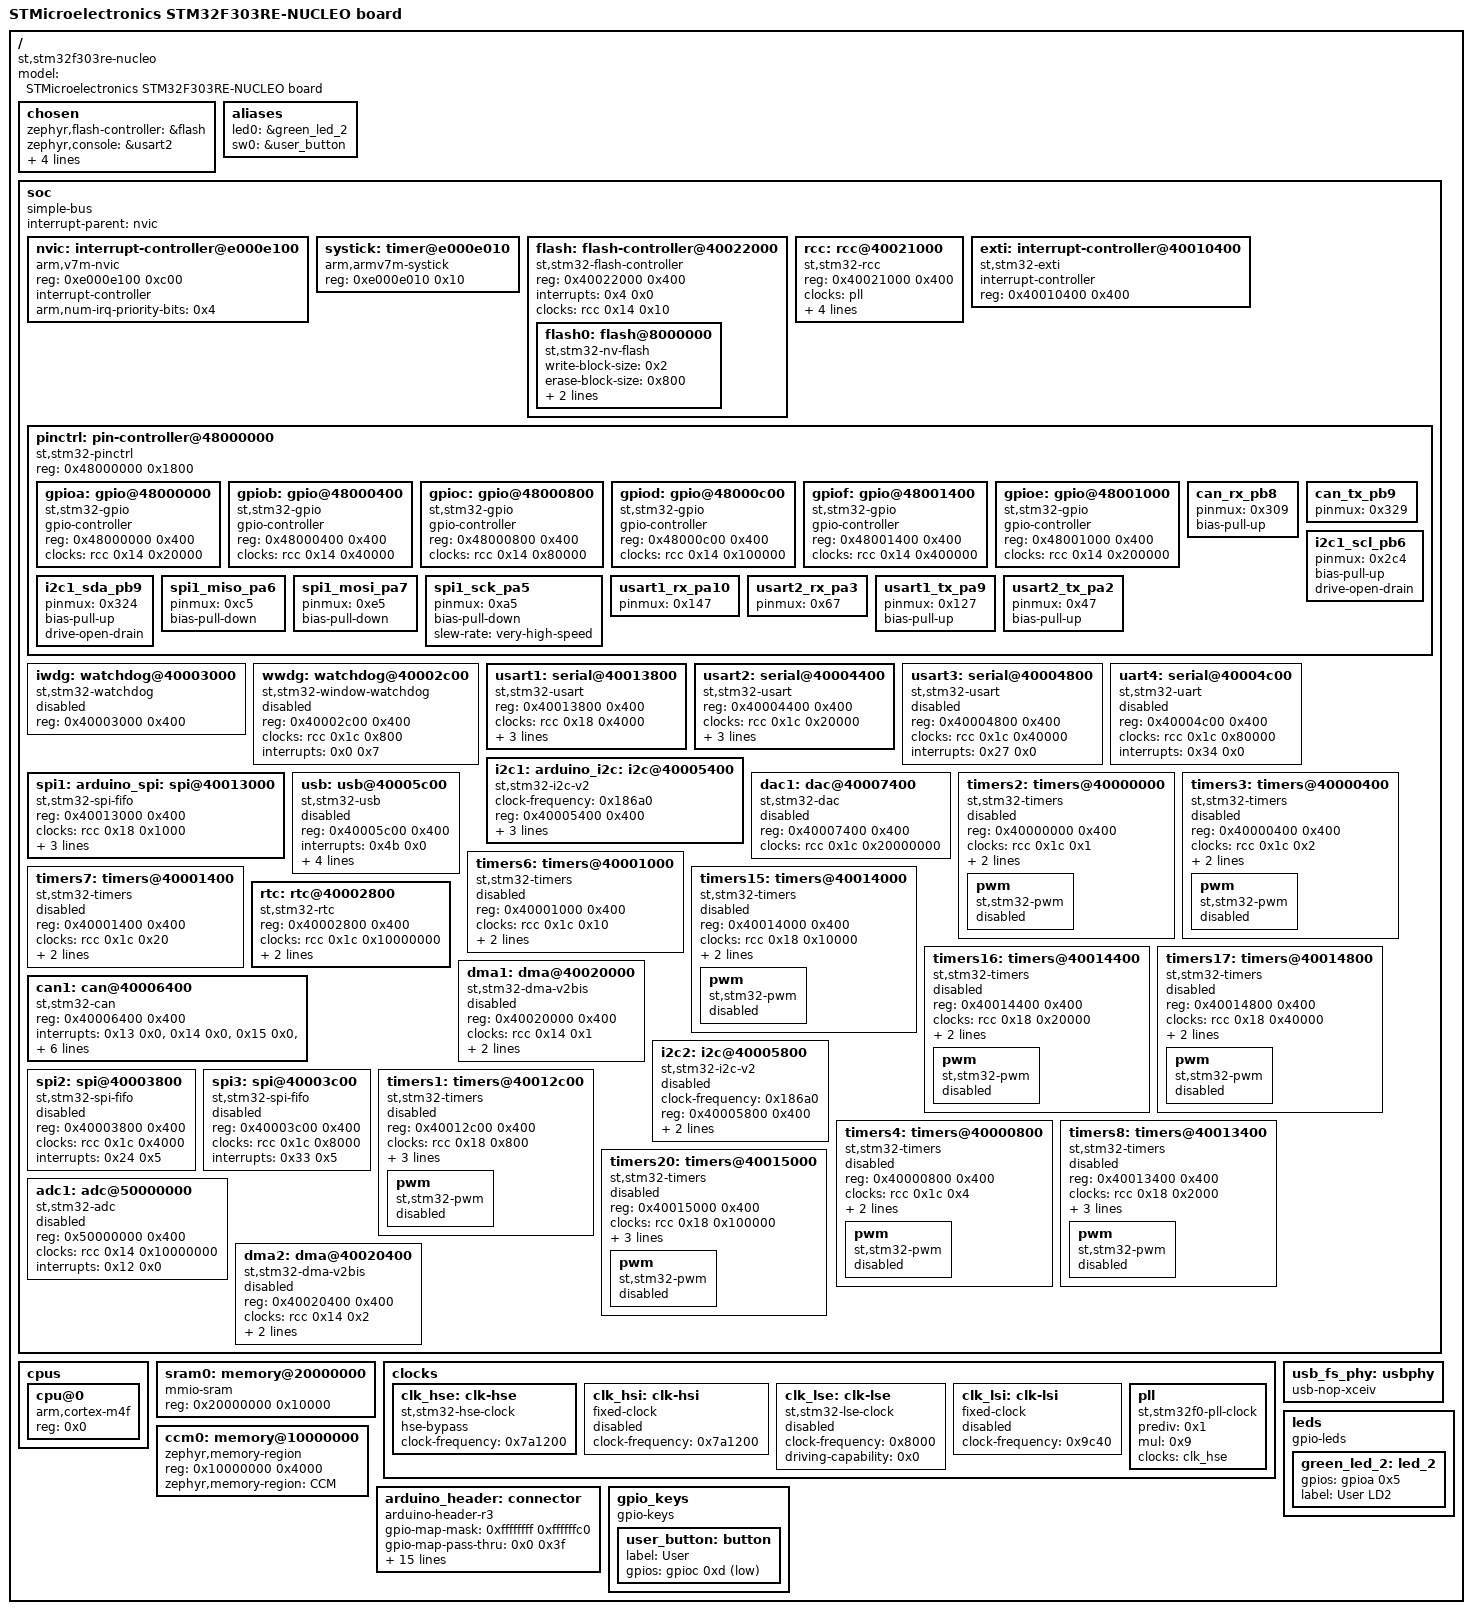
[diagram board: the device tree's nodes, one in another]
/dts-v1/;

/ {
	#address-cells = < 0x1 >;
	#size-cells = < 0x1 >;
	model = "STMicroelectronics STM32F303RE-NUCLEO board";
	compatible = "st,stm32f303re-nucleo";
	chosen {
		zephyr,flash-controller = &flash;
		zephyr,console = &usart2;
		zephyr,shell-uart = &usart2;
		zephyr,sram = &sram0;
		zephyr,flash = &flash0;
		zephyr,canbus = &can1;
	};
	aliases {
		led0 = &green_led_2;
		sw0 = &user_button;
	};
	soc {
		#address-cells = < 0x1 >;
		#size-cells = < 0x1 >;
		compatible = "simple-bus";
		interrupt-parent = < &nvic >;
		ranges;
		nvic: interrupt-controller@e000e100 {
			#address-cells = < 0x1 >;
			compatible = "arm,v7m-nvic";
			reg = < 0xe000e100 0xc00 >;
			interrupt-controller;
			#interrupt-cells = < 0x2 >;
			arm,num-irq-priority-bits = < 0x4 >;
			phandle = < 0x1 >;
		};
		systick: timer@e000e010 {
			compatible = "arm,armv7m-systick";
			reg = < 0xe000e010 0x10 >;
		};
		flash: flash-controller@40022000 {
			compatible = "st,stm32-flash-controller", "st,stm32f3-flash-controller";
			reg = < 0x40022000 0x400 >;
			interrupts = < 0x4 0x0 >;
			clocks = < &rcc 0x14 0x10 >;
			#address-cells = < 0x1 >;
			#size-cells = < 0x1 >;
			flash0: flash@8000000 {
				compatible = "st,stm32-nv-flash", "soc-nv-flash";
				write-block-size = < 0x2 >;
				erase-block-size = < 0x800 >;
				max-erase-time = < 0x28 >;
				reg = < 0x8000000 0x80000 >;
			};
		};
		rcc: rcc@40021000 {
			compatible = "st,stm32-rcc";
			#clock-cells = < 0x2 >;
			reg = < 0x40021000 0x400 >;
			clocks = < &pll >;
			clock-frequency = < 0x44aa200 >;
			ahb-prescaler = < 0x1 >;
			apb1-prescaler = < 0x2 >;
			apb2-prescaler = < 0x1 >;
			phandle = < 0x2 >;
		};
		exti: interrupt-controller@40010400 {
			compatible = "st,stm32-exti";
			interrupt-controller;
			#interrupt-cells = < 0x1 >;
			reg = < 0x40010400 0x400 >;
		};
		pinctrl: pin-controller@48000000 {
			compatible = "st,stm32-pinctrl";
			#address-cells = < 0x1 >;
			#size-cells = < 0x1 >;
			reg = < 0x48000000 0x1800 >;
			gpioa: gpio@48000000 {
				compatible = "st,stm32-gpio";
				gpio-controller;
				#gpio-cells = < 0x2 >;
				reg = < 0x48000000 0x400 >;
				clocks = < &rcc 0x14 0x20000 >;
				phandle = < 0x11 >;
			};
			gpiob: gpio@48000400 {
				compatible = "st,stm32-gpio";
				gpio-controller;
				#gpio-cells = < 0x2 >;
				reg = < 0x48000400 0x400 >;
				clocks = < &rcc 0x14 0x40000 >;
				phandle = < 0x12 >;
			};
			gpioc: gpio@48000800 {
				compatible = "st,stm32-gpio";
				gpio-controller;
				#gpio-cells = < 0x2 >;
				reg = < 0x48000800 0x400 >;
				clocks = < &rcc 0x14 0x80000 >;
				phandle = < 0x13 >;
			};
			gpiod: gpio@48000c00 {
				compatible = "st,stm32-gpio";
				gpio-controller;
				#gpio-cells = < 0x2 >;
				reg = < 0x48000c00 0x400 >;
				clocks = < &rcc 0x14 0x100000 >;
			};
			gpiof: gpio@48001400 {
				compatible = "st,stm32-gpio";
				gpio-controller;
				#gpio-cells = < 0x2 >;
				reg = < 0x48001400 0x400 >;
				clocks = < &rcc 0x14 0x400000 >;
			};
			gpioe: gpio@48001000 {
				compatible = "st,stm32-gpio";
				gpio-controller;
				#gpio-cells = < 0x2 >;
				reg = < 0x48001000 0x400 >;
				clocks = < &rcc 0x14 0x200000 >;
			};
			can_rx_pb8: can_rx_pb8 {
				pinmux = < 0x309 >;
				bias-pull-up;
				phandle = < 0xe >;
			};
			can_tx_pb9: can_tx_pb9 {
				pinmux = < 0x329 >;
				phandle = < 0xf >;
			};
			i2c1_scl_pb6: i2c1_scl_pb6 {
				pinmux = < 0x2c4 >;
				bias-pull-up;
				drive-open-drain;
				phandle = < 0x8 >;
			};
			i2c1_sda_pb9: i2c1_sda_pb9 {
				pinmux = < 0x324 >;
				bias-pull-up;
				drive-open-drain;
				phandle = < 0x9 >;
			};
			spi1_miso_pa6: spi1_miso_pa6 {
				pinmux = < 0xc5 >;
				bias-pull-down;
				phandle = < 0xb >;
			};
			spi1_mosi_pa7: spi1_mosi_pa7 {
				pinmux = < 0xe5 >;
				bias-pull-down;
				phandle = < 0xa >;
			};
			spi1_sck_pa5: spi1_sck_pa5 {
				pinmux = < 0xa5 >;
				bias-pull-down;
				slew-rate = "very-high-speed";
				phandle = < 0xc >;
			};
			usart1_rx_pa10: usart1_rx_pa10 {
				pinmux = < 0x147 >;
				phandle = < 0x5 >;
			};
			usart2_rx_pa3: usart2_rx_pa3 {
				pinmux = < 0x67 >;
				phandle = < 0x7 >;
			};
			usart1_tx_pa9: usart1_tx_pa9 {
				pinmux = < 0x127 >;
				bias-pull-up;
				phandle = < 0x4 >;
			};
			usart2_tx_pa2: usart2_tx_pa2 {
				pinmux = < 0x47 >;
				bias-pull-up;
				phandle = < 0x6 >;
			};
		};
		iwdg: watchdog@40003000 {
			compatible = "st,stm32-watchdog";
			reg = < 0x40003000 0x400 >;
			status = "disabled";
		};
		wwdg: watchdog@40002c00 {
			compatible = "st,stm32-window-watchdog";
			reg = < 0x40002c00 0x400 >;
			clocks = < &rcc 0x1c 0x800 >;
			interrupts = < 0x0 0x7 >;
			status = "disabled";
		};
		usart1: serial@40013800 {
			compatible = "st,stm32-usart", "st,stm32-uart";
			reg = < 0x40013800 0x400 >;
			clocks = < &rcc 0x18 0x4000 >;
			interrupts = < 0x25 0x0 >;
			status = "okay";
			pinctrl-0 = < &usart1_tx_pa9 &usart1_rx_pa10 >;
			pinctrl-names = "default";
			current-speed = < 0x1c200 >;
		};
		usart2: serial@40004400 {
			compatible = "st,stm32-usart", "st,stm32-uart";
			reg = < 0x40004400 0x400 >;
			clocks = < &rcc 0x1c 0x20000 >;
			interrupts = < 0x26 0x0 >;
			status = "okay";
			pinctrl-0 = < &usart2_tx_pa2 &usart2_rx_pa3 >;
			pinctrl-names = "default";
			current-speed = < 0x1c200 >;
		};
		usart3: serial@40004800 {
			compatible = "st,stm32-usart", "st,stm32-uart";
			reg = < 0x40004800 0x400 >;
			clocks = < &rcc 0x1c 0x40000 >;
			interrupts = < 0x27 0x0 >;
			status = "disabled";
		};
		uart4: serial@40004c00 {
			compatible = "st,stm32-uart";
			reg = < 0x40004c00 0x400 >;
			clocks = < &rcc 0x1c 0x80000 >;
			interrupts = < 0x34 0x0 >;
			status = "disabled";
		};
		i2c1: arduino_i2c: i2c@40005400 {
			compatible = "st,stm32-i2c-v2";
			clock-frequency = < 0x186a0 >;
			#address-cells = < 0x1 >;
			#size-cells = < 0x0 >;
			reg = < 0x40005400 0x400 >;
			clocks = < &rcc 0x1c 0x200000 >;
			interrupts = < 0x1f 0x0 >, < 0x20 0x0 >;
			interrupt-names = "event", "error";
			status = "okay";
			pinctrl-0 = < &i2c1_scl_pb6 &i2c1_sda_pb9 >;
			pinctrl-names = "default";
		};
		spi1: arduino_spi: spi@40013000 {
			compatible = "st,stm32-spi-fifo", "st,stm32-spi";
			#address-cells = < 0x1 >;
			#size-cells = < 0x0 >;
			reg = < 0x40013000 0x400 >;
			clocks = < &rcc 0x18 0x1000 >;
			interrupts = < 0x23 0x5 >;
			status = "okay";
			pinctrl-0 = < &spi1_mosi_pa7 &spi1_miso_pa6 &spi1_sck_pa5 >;
			pinctrl-names = "default";
		};
		dac1: dac@40007400 {
			compatible = "st,stm32-dac";
			reg = < 0x40007400 0x400 >;
			clocks = < &rcc 0x1c 0x20000000 >;
			status = "disabled";
			#io-channel-cells = < 0x1 >;
		};
		usb: usb@40005c00 {
			compatible = "st,stm32-usb";
			reg = < 0x40005c00 0x400 >;
			interrupts = < 0x4b 0x0 >;
			interrupt-names = "usb";
			num-bidir-endpoints = < 0x8 >;
			ram-size = < 0x200 >;
			phys = < &usb_fs_phy >;
			clocks = < &rcc 0x1c 0x800000 >;
			status = "disabled";
		};
		timers2: timers@40000000 {
			compatible = "st,stm32-timers";
			reg = < 0x40000000 0x400 >;
			clocks = < &rcc 0x1c 0x1 >;
			interrupts = < 0x1c 0x0 >;
			interrupt-names = "global";
			st,prescaler = < 0x0 >;
			status = "disabled";
			pwm {
				compatible = "st,stm32-pwm";
				status = "disabled";
				#pwm-cells = < 0x3 >;
			};
		};
		timers3: timers@40000400 {
			compatible = "st,stm32-timers";
			reg = < 0x40000400 0x400 >;
			clocks = < &rcc 0x1c 0x2 >;
			interrupts = < 0x1d 0x0 >;
			interrupt-names = "global";
			st,prescaler = < 0x0 >;
			status = "disabled";
			pwm {
				compatible = "st,stm32-pwm";
				status = "disabled";
				#pwm-cells = < 0x3 >;
			};
		};
		timers6: timers@40001000 {
			compatible = "st,stm32-timers";
			reg = < 0x40001000 0x400 >;
			clocks = < &rcc 0x1c 0x10 >;
			interrupts = < 0x36 0x0 >;
			interrupt-names = "global";
			st,prescaler = < 0x0 >;
			status = "disabled";
		};
		timers7: timers@40001400 {
			compatible = "st,stm32-timers";
			reg = < 0x40001400 0x400 >;
			clocks = < &rcc 0x1c 0x20 >;
			interrupts = < 0x37 0x0 >;
			interrupt-names = "global";
			st,prescaler = < 0x0 >;
			status = "disabled";
		};
		timers15: timers@40014000 {
			compatible = "st,stm32-timers";
			reg = < 0x40014000 0x400 >;
			clocks = < &rcc 0x18 0x10000 >;
			interrupts = < 0x18 0x0 >;
			interrupt-names = "global";
			st,prescaler = < 0x0 >;
			status = "disabled";
			pwm {
				compatible = "st,stm32-pwm";
				status = "disabled";
				#pwm-cells = < 0x3 >;
			};
		};
		timers16: timers@40014400 {
			compatible = "st,stm32-timers";
			reg = < 0x40014400 0x400 >;
			clocks = < &rcc 0x18 0x20000 >;
			interrupts = < 0x19 0x0 >;
			interrupt-names = "global";
			st,prescaler = < 0x0 >;
			status = "disabled";
			pwm {
				compatible = "st,stm32-pwm";
				status = "disabled";
				#pwm-cells = < 0x3 >;
			};
		};
		timers17: timers@40014800 {
			compatible = "st,stm32-timers";
			reg = < 0x40014800 0x400 >;
			clocks = < &rcc 0x18 0x40000 >;
			interrupts = < 0x1a 0x0 >;
			interrupt-names = "global";
			st,prescaler = < 0x0 >;
			status = "disabled";
			pwm {
				compatible = "st,stm32-pwm";
				status = "disabled";
				#pwm-cells = < 0x3 >;
			};
		};
		rtc: rtc@40002800 {
			compatible = "st,stm32-rtc";
			reg = < 0x40002800 0x400 >;
			clocks = < &rcc 0x1c 0x10000000 >;
			interrupts = < 0x29 0x0 >;
			prescaler = < 0x8000 >;
			status = "okay";
		};
		can1: can@40006400 {
			compatible = "st,stm32-can";
			reg = < 0x40006400 0x400 >;
			interrupts = < 0x13 0x0 >, < 0x14 0x0 >, < 0x15 0x0 >, < 0x16 0x0 >;
			interrupt-names = "TX", "RX0", "RX1", "SCE";
			clocks = < &rcc 0x1c 0x2000000 >;
			status = "okay";
			sjw = < 0x1 >;
			sample-point = < 0x36b >;
			pinctrl-0 = < &can_rx_pb8 &can_tx_pb9 >;
			pinctrl-names = "default";
			bus-speed = < 0x1e848 >;
		};
		dma1: dma@40020000 {
			compatible = "st,stm32-dma-v2bis";
			#dma-cells = < 0x2 >;
			reg = < 0x40020000 0x400 >;
			clocks = < &rcc 0x14 0x1 >;
			interrupts = < 0xb 0x0 0xc 0x0 0xd 0x0 0xe 0x0 0xf 0x0 0x10 0x0 0x11 0x0 >;
			status = "disabled";
		};
		i2c2: i2c@40005800 {
			compatible = "st,stm32-i2c-v2";
			clock-frequency = < 0x186a0 >;
			#address-cells = < 0x1 >;
			#size-cells = < 0x0 >;
			reg = < 0x40005800 0x400 >;
			clocks = < &rcc 0x1c 0x400000 >;
			interrupts = < 0x21 0x0 >, < 0x22 0x0 >;
			interrupt-names = "event", "error";
			status = "disabled";
		};
		spi2: spi@40003800 {
			compatible = "st,stm32-spi-fifo", "st,stm32-spi";
			#address-cells = < 0x1 >;
			#size-cells = < 0x0 >;
			reg = < 0x40003800 0x400 >;
			clocks = < &rcc 0x1c 0x4000 >;
			interrupts = < 0x24 0x5 >;
			status = "disabled";
		};
		spi3: spi@40003c00 {
			compatible = "st,stm32-spi-fifo", "st,stm32-spi";
			#address-cells = < 0x1 >;
			#size-cells = < 0x0 >;
			reg = < 0x40003c00 0x400 >;
			clocks = < &rcc 0x1c 0x8000 >;
			interrupts = < 0x33 0x5 >;
			status = "disabled";
		};
		timers1: timers@40012c00 {
			compatible = "st,stm32-timers";
			reg = < 0x40012c00 0x400 >;
			clocks = < &rcc 0x18 0x800 >;
			interrupts = < 0x18 0x0 >, < 0x19 0x0 >, < 0x1a 0x0 >, < 0x1b 0x0 >;
			interrupt-names = "brk", "up", "trgcom", "cc";
			st,prescaler = < 0x0 >;
			status = "disabled";
			pwm {
				compatible = "st,stm32-pwm";
				status = "disabled";
				#pwm-cells = < 0x3 >;
			};
		};
		timers4: timers@40000800 {
			compatible = "st,stm32-timers";
			reg = < 0x40000800 0x400 >;
			clocks = < &rcc 0x1c 0x4 >;
			interrupts = < 0x1e 0x0 >;
			interrupt-names = "global";
			st,prescaler = < 0x0 >;
			status = "disabled";
			pwm {
				compatible = "st,stm32-pwm";
				status = "disabled";
				#pwm-cells = < 0x3 >;
			};
		};
		timers8: timers@40013400 {
			compatible = "st,stm32-timers";
			reg = < 0x40013400 0x400 >;
			clocks = < &rcc 0x18 0x2000 >;
			interrupts = < 0x2b 0x0 >, < 0x2c 0x0 >, < 0x2d 0x0 >, < 0x2e 0x0 >;
			interrupt-names = "brk", "up", "trgcom", "cc";
			st,prescaler = < 0x0 >;
			status = "disabled";
			pwm {
				compatible = "st,stm32-pwm";
				status = "disabled";
				#pwm-cells = < 0x3 >;
			};
		};
		timers20: timers@40015000 {
			compatible = "st,stm32-timers";
			reg = < 0x40015000 0x400 >;
			clocks = < &rcc 0x18 0x100000 >;
			interrupts = < 0x4d 0x0 >, < 0x4e 0x0 >, < 0x4f 0x0 >, < 0x50 0x0 >;
			interrupt-names = "brk", "up", "trgcom", "cc";
			st,prescaler = < 0x0 >;
			status = "disabled";
			pwm {
				compatible = "st,stm32-pwm";
				status = "disabled";
				#pwm-cells = < 0x3 >;
			};
		};
		adc1: adc@50000000 {
			compatible = "st,stm32-adc";
			reg = < 0x50000000 0x400 >;
			clocks = < &rcc 0x14 0x10000000 >;
			interrupts = < 0x12 0x0 >;
			status = "disabled";
			#io-channel-cells = < 0x1 >;
		};
		dma2: dma@40020400 {
			compatible = "st,stm32-dma-v2bis";
			#dma-cells = < 0x2 >;
			reg = < 0x40020400 0x400 >;
			clocks = < &rcc 0x14 0x2 >;
			interrupts = < 0x38 0x0 0x39 0x0 0x3a 0x0 0x3b 0x0 0x3c 0x0 >;
			status = "disabled";
		};
	};
	cpus {
		#address-cells = < 0x1 >;
		#size-cells = < 0x0 >;
		cpu@0 {
			device_type = "cpu";
			compatible = "arm,cortex-m4f";
			reg = < 0x0 >;
		};
	};
	sram0: memory@20000000 {
		compatible = "mmio-sram";
		reg = < 0x20000000 0x10000 >;
	};
	clocks {
		clk_hse: clk-hse {
			#clock-cells = < 0x0 >;
			compatible = "st,stm32-hse-clock";
			status = "okay";
			hse-bypass;
			clock-frequency = < 0x7a1200 >;
			phandle = < 0x10 >;
		};
		clk_hsi: clk-hsi {
			#clock-cells = < 0x0 >;
			compatible = "fixed-clock";
			clock-frequency = < 0x7a1200 >;
			status = "disabled";
		};
		clk_lse: clk-lse {
			#clock-cells = < 0x0 >;
			compatible = "st,stm32-lse-clock";
			clock-frequency = < 0x8000 >;
			driving-capability = < 0x0 >;
			status = "disabled";
		};
		clk_lsi: clk-lsi {
			#clock-cells = < 0x0 >;
			compatible = "fixed-clock";
			clock-frequency = < 0x9c40 >;
			status = "disabled";
		};
		pll: pll {
			#clock-cells = < 0x0 >;
			compatible = "st,stm32f0-pll-clock";
			status = "okay";
			prediv = < 0x1 >;
			mul = < 0x9 >;
			clocks = < &clk_hse >;
			phandle = < 0x3 >;
		};
	};
	usb_fs_phy: usbphy {
		compatible = "usb-nop-xceiv";
		#phy-cells = < 0x0 >;
		phandle = < 0xd >;
	};
	ccm0: memory@10000000 {
		compatible = "zephyr,memory-region", "st,stm32-ccm";
		reg = < 0x10000000 0x4000 >;
		zephyr,memory-region = "CCM";
	};
	arduino_header: connector {
		compatible = "arduino-header-r3";
		#gpio-cells = < 0x2 >;
		gpio-map-mask = < 0xffffffff 0xffffffc0 >;
		gpio-map-pass-thru = < 0x0 0x3f >;
		gpio-map = < 0x0 0x0 &gpioa 0x0 0x0 >, < 0x1 0x0 &gpioa 0x1 0x0 >, < 0x2 0x0 &gpioa 0x4 0x0 >, < 0x3 0x0 &gpiob 0x0 0x0 >, < 0x4 0x0 &gpioc 0x1 0x0 >, < 0x5 0x0 &gpioc 0x0 0x0 >, < 0x6 0x0 &gpioa 0x3 0x0 >, < 0x7 0x0 &gpioa 0x2 0x0 >, < 0x8 0x0 &gpioa 0xa 0x0 >, < 0x9 0x0 &gpiob 0x3 0x0 >, < 0xa 0x0 &gpiob 0x5 0x0 >, < 0xb 0x0 &gpiob 0x4 0x0 >, < 0xc 0x0 &gpiob 0xa 0x0 >, < 0xd 0x0 &gpioa 0x8 0x0 >, < 0xe 0x0 &gpioa 0x9 0x0 >, < 0xf 0x0 &gpioc 0x7 0x0 >, < 0x10 0x0 &gpiob 0x6 0x0 >, < 0x11 0x0 &gpiob 0xf 0x0 >, < 0x12 0x0 &gpiob 0xe 0x0 >, < 0x13 0x0 &gpiob 0xd 0x0 >, < 0x14 0x0 &gpiob 0x9 0x0 >, < 0x15 0x0 &gpiob 0x8 0x0 >;
	};
	leds {
		compatible = "gpio-leds";
		green_led_2: led_2 {
			gpios = < &gpioa 0x5 0x0 >;
			label = "User LD2";
		};
	};
	gpio_keys {
		compatible = "gpio-keys";
		user_button: button {
			label = "User";
			gpios = < &gpioc 0xd 0x1 >;
		};
	};
};
